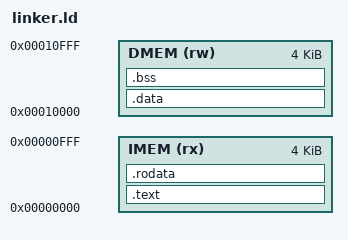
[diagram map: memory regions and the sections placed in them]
/*==============================================================================
 * linker.ld — RV32I 教学 core 链接脚本
 *
 * 内存布局：
 *   IMEM (0x00000000) : .text
 *   DMEM (0x00010000) : .data / .bss
 *
 * 当前 simple_rom/simple_ram 默认 ADDR_WIDTH=10，即 1024 个 32-bit word，
 * 每块 memory 容量为 4 KiB。链接脚本先与这个仿真 memory model 保持一致。
 *
 * 用法：
 *   ${CROSS_COMPILE}ld -T sw/linker/linker.ld -o program.elf program.o
 *============================================================================*/

OUTPUT_ARCH(riscv)
ENTRY(_start)

MEMORY
{
    /* 指令存储器：起始地址 0x00000000，4 KiB */
    IMEM (rx)  : ORIGIN = 0x00000000, LENGTH = 4K

    /* 数据存储器：起始地址 0x00010000，4 KiB */
    DMEM (rw)  : ORIGIN = 0x00010000, LENGTH = 4K
}

SECTIONS
{
    /*----------------------------------------------------------------------
     * .text — 代码段，放在 IMEM
     *--------------------------------------------------------------------*/
    .text : ALIGN(4)
    {
        *(.text.init)          /* reset 后执行的入口代码必须放在最前面 */
        *(.text)               /* 所有输入文件的 .text 段 */
        *(.text.*)             /* 诸如 .text.some_function 的子段 */
    } > IMEM

    /*----------------------------------------------------------------------
     * .rodata — 只读数据，可以放 IMEM 或 DMEM，这里放 IMEM
     *--------------------------------------------------------------------*/
    .rodata : ALIGN(4)
    {
        *(.rodata)
        *(.rodata.*)
    } > IMEM

    /*----------------------------------------------------------------------
     * .data — 已初始化全局/静态数据，放在 DMEM
     *--------------------------------------------------------------------*/
    .data : ALIGN(4)
    {
        __data_start = .;
        *(.data)
        *(.data.*)
        __data_end = .;
    } > DMEM

    /*----------------------------------------------------------------------
     * .bss — 未初始化全局/静态数据，放在 DMEM
     *--------------------------------------------------------------------*/
    .bss : ALIGN(4)
    {
        __bss_start = .;
        *(.bss)
        *(.bss.*)
        *(COMMON)
        __bss_end = .;
    } > DMEM

    /*----------------------------------------------------------------------
     * 堆栈指针初始化：_sp = DMEM 末尾（向下生长）
     *--------------------------------------------------------------------*/
    __sp = ORIGIN(DMEM) + LENGTH(DMEM);
}
